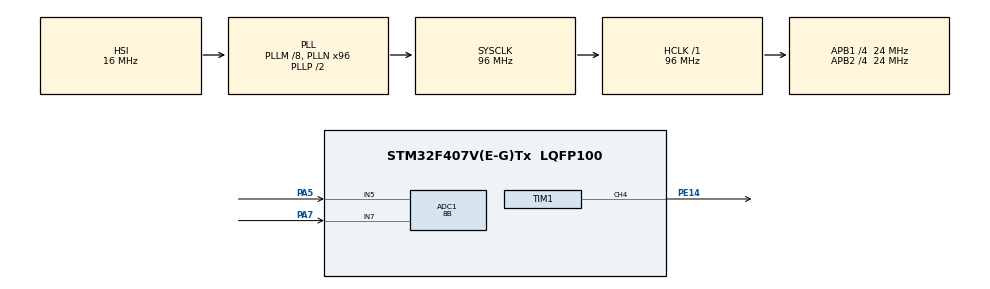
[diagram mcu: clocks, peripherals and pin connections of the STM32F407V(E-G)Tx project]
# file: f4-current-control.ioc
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ADC1.Channel-1\#ChannelRegularConversion=ADC_CHANNEL_5
ADC1.Channel-2\#ChannelRegularConversion=ADC_CHANNEL_7
ADC1.DMAContinuousRequests=ENABLE
ADC1.ExternalTrigConv=ADC_EXTERNALTRIGCONV_T8_TRGO
ADC1.NbrOfConversion=2
ADC1.NbrOfConversionFlag=1
ADC1.Rank-1\#ChannelRegularConversion=1
ADC1.Rank-2\#ChannelRegularConversion=2
ADC1.Resolution=ADC_RESOLUTION_8B
ADC1.SamplingTime-1\#ChannelRegularConversion=ADC_SAMPLETIME_3CYCLES
ADC1.SamplingTime-2\#ChannelRegularConversion=ADC_SAMPLETIME_3CYCLES
ADC1.master=1
Dma.ADC1.0.Direction=DMA_PERIPH_TO_MEMORY
Dma.ADC1.0.FIFOMode=DMA_FIFOMODE_DISABLE
Dma.ADC1.0.Instance=DMA2_Stream0
Dma.ADC1.0.MemDataAlignment=DMA_MDATAALIGN_BYTE
Dma.ADC1.0.MemInc=DMA_MINC_ENABLE
Dma.ADC1.0.Mode=DMA_CIRCULAR
Dma.ADC1.0.PeriphDataAlignment=DMA_PDATAALIGN_BYTE
Dma.ADC1.0.PeriphInc=DMA_PINC_DISABLE
Dma.ADC1.0.Priority=DMA_PRIORITY_LOW
Dma.Request0=ADC1
Mcu.Family=STM32F4
Mcu.Name=STM32F407V(E-G)Tx
Mcu.Package=LQFP100
NVIC.DMA2_Stream0_IRQn=true\:0\:0\:false\:false\:true\:false\:true\:true
NVIC.PriorityGroup=NVIC_PRIORITYGROUP_4
NVIC.TIM8_UP_TIM13_IRQn=true\:0\:0\:false\:false\:true\:true\:true\:true
PA5.Signal=ADCx_IN5
PA7.Signal=ADCx_IN7
PE14.Signal=S_TIM1_CH4
ProjectManager.HeapSize=0x200
ProjectManager.StackSize=0x400
ProjectManager.TargetToolchain=STM32CubeIDE
RCC.48MHZClocksFreq_Value=48000000
RCC.AHBFreq_Value=96000000
RCC.APB1CLKDivider=RCC_HCLK_DIV4
RCC.APB1Freq_Value=24000000
RCC.APB1TimFreq_Value=48000000
RCC.APB2CLKDivider=RCC_HCLK_DIV4
RCC.APB2Freq_Value=24000000
RCC.APB2TimFreq_Value=48000000
RCC.CortexFreq_Value=96000000
RCC.HCLKFreq_Value=96000000
RCC.HSE_VALUE=25000000
RCC.HSI_VALUE=16000000
RCC.LSE_VALUE=32768
RCC.PLLM=8
RCC.PLLN=96
RCC.SYSCLKFreq_VALUE=96000000
RCC.SYSCLKSource=RCC_SYSCLKSOURCE_PLLCLK
RCC.VCOOutputFreq_Value=192000000
SH.ADCx_IN5.0=ADC1_IN5,IN5
SH.ADCx_IN7.0=ADC1_IN7,IN7
SH.S_TIM1_CH4.0=TIM1_CH4,PWM Generation4 CH4
TIM1.Channel-PWM\ Generation4\ CH4=TIM_CHANNEL_4
TIM1.Period=255
TIM8.Period=1000
TIM8.Prescaler=48-1
TIM8.TIM_MasterOutputTrigger=TIM_TRGO_UPDATE
VP_TIM1_VS_ClockSourceINT.Mode=Internal
VP_TIM8_VS_ClockSourceINT.Mode=Internal
board=custom

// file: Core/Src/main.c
/* USER CODE BEGIN Header */
/**
  ******************************************************************************
  * @file           : main.c
  * @brief          : Main program body
  ******************************************************************************
  * @attention
  *
  * Copyright (c) 2026 STMicroelectronics.
  * All rights reserved.
  *
  * This software is licensed under terms that can be found in the LICENSE file
  * in the root directory of this software component.
  * If no LICENSE file comes with this software, it is provided AS-IS.
  *
  ******************************************************************************
  */
/* USER CODE END Header */
#include "main.h"

ADC_HandleTypeDef hadc1;
DMA_HandleTypeDef hdma_adc1;

TIM_HandleTypeDef htim1;
TIM_HandleTypeDef htim8;

/* USER CODE BEGIN PV */

uint16_t value = 0;
uint8_t maxSteps = 255;
uint8_t numSteps = 250;
float maxVoltage = 3.0;
float targetVoltage = 3.0;
uint8_t maxValue = 255;
uint8_t step = 1;
uint8_t endDelay = 1; //steps of delay

uint8_t adcValue = 0;
uint8_t adcValues[12][2];

/* USER CODE END PV */

void SystemClock_Config(void);
static void MX_GPIO_Init(void);
static void MX_DMA_Init(void);
static void MX_TIM1_Init(void);
static void MX_ADC1_Init(void);
static void MX_TIM8_Init(void);

int main(void)
{

  /* MCU Configuration--------------------------------------------------------*/

  /* Reset of all peripherals, Initializes the Flash interface and the Systick. */
  HAL_Init();

  /* Configure the system clock */
  SystemClock_Config();

  /* Initialize all configured peripherals */
  MX_GPIO_Init();
  MX_DMA_Init();
  MX_TIM1_Init();
  MX_ADC1_Init();
  MX_TIM8_Init();
  /* USER CODE BEGIN 2 */

  HAL_TIM_Base_Start_IT(&htim8);
  HAL_TIM_PWM_Start(&htim1, TIM_CHANNEL_4);

//  HAL_ADC_Start_DMA(&hadc1, (uint32_t*)&adcValue, 1);
  HAL_ADC_Start_DMA(&hadc1, (uint32_t*)adcValues, 24);

  // var init test measurments
  targetVoltage = 1;
  numSteps = 10;

  /* USER CODE END 2 */

  /* Infinite loop */
  /* USER CODE BEGIN WHILE */
  while (1)
  {
	  maxValue = targetVoltage/maxVoltage * maxSteps;
	  step = maxValue / numSteps;
    /* USER CODE END WHILE */

  }
}

void SystemClock_Config(void)
{
  RCC_OscInitTypeDef RCC_OscInitStruct = {0};
  RCC_ClkInitTypeDef RCC_ClkInitStruct = {0};

  /** Configure the main internal regulator output voltage
  */
  __HAL_RCC_PWR_CLK_ENABLE();
  __HAL_PWR_VOLTAGESCALING_CONFIG(PWR_REGULATOR_VOLTAGE_SCALE1);

  /** Initializes the RCC Oscillators according to the specified parameters
  * in the RCC_OscInitTypeDef structure.
  */
  RCC_OscInitStruct.OscillatorType = RCC_OSCILLATORTYPE_HSI;
  RCC_OscInitStruct.HSIState = RCC_HSI_ON;
  RCC_OscInitStruct.HSICalibrationValue = RCC_HSICALIBRATION_DEFAULT;
  RCC_OscInitStruct.PLL.PLLState = RCC_PLL_ON;
  RCC_OscInitStruct.PLL.PLLSource = RCC_PLLSOURCE_HSI;
  RCC_OscInitStruct.PLL.PLLM = 8;
  RCC_OscInitStruct.PLL.PLLN = 96;
  RCC_OscInitStruct.PLL.PLLP = RCC_PLLP_DIV2;
  RCC_OscInitStruct.PLL.PLLQ = 4;
  if (HAL_RCC_OscConfig(&RCC_OscInitStruct) != HAL_OK)
  {
    Error_Handler();
  }

  /** Initializes the CPU, AHB and APB buses clocks
  */
  RCC_ClkInitStruct.ClockType = RCC_CLOCKTYPE_HCLK|RCC_CLOCKTYPE_SYSCLK
                              |RCC_CLOCKTYPE_PCLK1|RCC_CLOCKTYPE_PCLK2;
  RCC_ClkInitStruct.SYSCLKSource = RCC_SYSCLKSOURCE_PLLCLK;
  RCC_ClkInitStruct.AHBCLKDivider = RCC_SYSCLK_DIV1;
  RCC_ClkInitStruct.APB1CLKDivider = RCC_HCLK_DIV4;
  RCC_ClkInitStruct.APB2CLKDivider = RCC_HCLK_DIV4;

  if (HAL_RCC_ClockConfig(&RCC_ClkInitStruct, FLASH_LATENCY_3) != HAL_OK)
  {
    Error_Handler();
  }
}

static void MX_ADC1_Init(void)
{

  ADC_ChannelConfTypeDef sConfig = {0};

  /** Configure the global features of the ADC (Clock, Resolution, Data Alignment and number of conversion)
  */
  hadc1.Instance = ADC1;
  hadc1.Init.ClockPrescaler = ADC_CLOCK_SYNC_PCLK_DIV2;
  hadc1.Init.Resolution = ADC_RESOLUTION_8B;
  hadc1.Init.ScanConvMode = ENABLE;
  hadc1.Init.ContinuousConvMode = DISABLE;
  hadc1.Init.DiscontinuousConvMode = DISABLE;
  hadc1.Init.ExternalTrigConvEdge = ADC_EXTERNALTRIGCONVEDGE_RISING;
  hadc1.Init.ExternalTrigConv = ADC_EXTERNALTRIGCONV_T8_TRGO;
  hadc1.Init.DataAlign = ADC_DATAALIGN_RIGHT;
  hadc1.Init.NbrOfConversion = 2;
  hadc1.Init.DMAContinuousRequests = ENABLE;
  hadc1.Init.EOCSelection = ADC_EOC_SINGLE_CONV;
  if (HAL_ADC_Init(&hadc1) != HAL_OK)
  {
    Error_Handler();
  }

  /** Configure for the selected ADC regular channel its corresponding rank in the sequencer and its sample time.
  */
  sConfig.Channel = ADC_CHANNEL_5;
  sConfig.Rank = 1;
  sConfig.SamplingTime = ADC_SAMPLETIME_3CYCLES;
  if (HAL_ADC_ConfigChannel(&hadc1, &sConfig) != HAL_OK)
  {
    Error_Handler();
  }

  /** Configure for the selected ADC regular channel its corresponding rank in the sequencer and its sample time.
  */
  sConfig.Channel = ADC_CHANNEL_7;
  sConfig.Rank = 2;
  if (HAL_ADC_ConfigChannel(&hadc1, &sConfig) != HAL_OK)
  {
    Error_Handler();
  }

}

static void MX_TIM1_Init(void)
{

  TIM_ClockConfigTypeDef sClockSourceConfig = {0};
  TIM_MasterConfigTypeDef sMasterConfig = {0};
  TIM_OC_InitTypeDef sConfigOC = {0};
  TIM_BreakDeadTimeConfigTypeDef sBreakDeadTimeConfig = {0};

  htim1.Instance = TIM1;
  htim1.Init.Prescaler = 0;
  htim1.Init.CounterMode = TIM_COUNTERMODE_UP;
  htim1.Init.Period = 255;
  htim1.Init.ClockDivision = TIM_CLOCKDIVISION_DIV1;
  htim1.Init.RepetitionCounter = 0;
  htim1.Init.AutoReloadPreload = TIM_AUTORELOAD_PRELOAD_DISABLE;
  if (HAL_TIM_Base_Init(&htim1) != HAL_OK)
  {
    Error_Handler();
  }
  sClockSourceConfig.ClockSource = TIM_CLOCKSOURCE_INTERNAL;
  if (HAL_TIM_ConfigClockSource(&htim1, &sClockSourceConfig) != HAL_OK)
  {
    Error_Handler();
  }
  if (HAL_TIM_PWM_Init(&htim1) != HAL_OK)
  {
    Error_Handler();
  }
  sMasterConfig.MasterOutputTrigger = TIM_TRGO_RESET;
  sMasterConfig.MasterSlaveMode = TIM_MASTERSLAVEMODE_DISABLE;
  if (HAL_TIMEx_MasterConfigSynchronization(&htim1, &sMasterConfig) != HAL_OK)
  {
    Error_Handler();
  }
  sConfigOC.OCMode = TIM_OCMODE_PWM1;
  sConfigOC.Pulse = 0;
  sConfigOC.OCPolarity = TIM_OCPOLARITY_HIGH;
  sConfigOC.OCFastMode = TIM_OCFAST_DISABLE;
  sConfigOC.OCIdleState = TIM_OCIDLESTATE_RESET;
  sConfigOC.OCNIdleState = TIM_OCNIDLESTATE_RESET;
  if (HAL_TIM_PWM_ConfigChannel(&htim1, &sConfigOC, TIM_CHANNEL_4) != HAL_OK)
  {
    Error_Handler();
  }
  sBreakDeadTimeConfig.OffStateRunMode = TIM_OSSR_DISABLE;
  sBreakDeadTimeConfig.OffStateIDLEMode = TIM_OSSI_DISABLE;
  sBreakDeadTimeConfig.LockLevel = TIM_LOCKLEVEL_OFF;
  sBreakDeadTimeConfig.DeadTime = 0;
  sBreakDeadTimeConfig.BreakState = TIM_BREAK_DISABLE;
  sBreakDeadTimeConfig.BreakPolarity = TIM_BREAKPOLARITY_HIGH;
  sBreakDeadTimeConfig.AutomaticOutput = TIM_AUTOMATICOUTPUT_DISABLE;
  if (HAL_TIMEx_ConfigBreakDeadTime(&htim1, &sBreakDeadTimeConfig) != HAL_OK)
  {
    Error_Handler();
  }
  HAL_TIM_MspPostInit(&htim1);

}

static void MX_TIM8_Init(void)
{

  TIM_ClockConfigTypeDef sClockSourceConfig = {0};
  TIM_MasterConfigTypeDef sMasterConfig = {0};

  htim8.Instance = TIM8;
  htim8.Init.Prescaler = 48-1;
  htim8.Init.CounterMode = TIM_COUNTERMODE_UP;
  htim8.Init.Period = 1000;
  htim8.Init.ClockDivision = TIM_CLOCKDIVISION_DIV1;
  htim8.Init.RepetitionCounter = 0;
  htim8.Init.AutoReloadPreload = TIM_AUTORELOAD_PRELOAD_DISABLE;
  if (HAL_TIM_Base_Init(&htim8) != HAL_OK)
  {
    Error_Handler();
  }
  sClockSourceConfig.ClockSource = TIM_CLOCKSOURCE_INTERNAL;
  if (HAL_TIM_ConfigClockSource(&htim8, &sClockSourceConfig) != HAL_OK)
  {
    Error_Handler();
  }
  sMasterConfig.MasterOutputTrigger = TIM_TRGO_UPDATE;
  sMasterConfig.MasterSlaveMode = TIM_MASTERSLAVEMODE_DISABLE;
  if (HAL_TIMEx_MasterConfigSynchronization(&htim8, &sMasterConfig) != HAL_OK)
  {
    Error_Handler();
  }

}

static void MX_DMA_Init(void)
{

  /* DMA controller clock enable */
  __HAL_RCC_DMA2_CLK_ENABLE();

  /* DMA interrupt init */
  /* DMA2_Stream0_IRQn interrupt configuration */
  HAL_NVIC_SetPriority(DMA2_Stream0_IRQn, 0, 0);
  HAL_NVIC_EnableIRQ(DMA2_Stream0_IRQn);

}

static void MX_GPIO_Init(void)
{

  /* GPIO Ports Clock Enable */
  __HAL_RCC_GPIOA_CLK_ENABLE();
  __HAL_RCC_GPIOE_CLK_ENABLE();

}

/* USER CODE BEGIN 4 */

void HAL_TIM_PeriodElapsedCallback(TIM_HandleTypeDef *htim){

	// compenstation for the capacitor discharge
	if (value > maxValue && value < maxValue+ endDelay*step){
		__HAL_TIM_SET_COMPARE(&htim1, TIM_CHANNEL_4, 0);
	}
	else if (value >= maxValue+ endDelay*step)
	{
		value =0;
	}
	else{
		__HAL_TIM_SET_COMPARE(&htim1, TIM_CHANNEL_4, value);
	}
	value+=step;
	//value = HAL_ADC_GetValue(&hadc1);
}

/* USER CODE END 4 */

void Error_Handler(void)
{
  __disable_irq();
  while (1)
  {
  }
}
